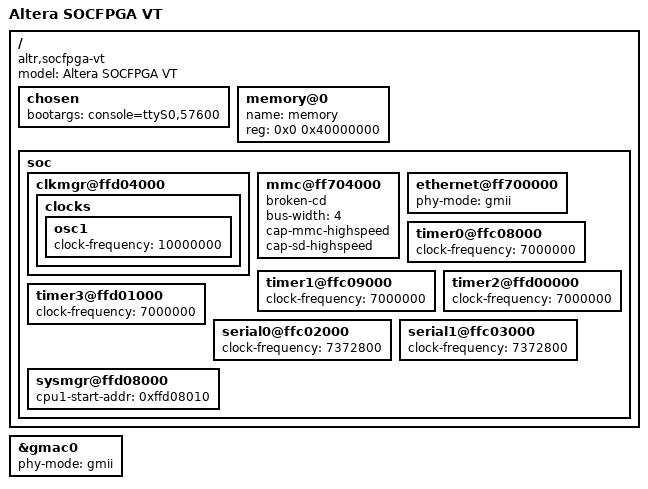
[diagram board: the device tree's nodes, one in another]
// SPDX-License-Identifier: GPL-2.0+
/*
 * Copyright (C) 2013 Altera Corporation <www.altera.com>
 */

/dts-v1/;
#include "socfpga.dtsi"

/ {
	model = "Altera SOCFPGA VT";
	compatible = "altr,socfpga-vt", "altr,socfpga";

	chosen {
		bootargs = "console=ttyS0,57600";
	};

	memory@0 {
		name = "memory";
		device_type = "memory";
		reg = <0x0 0x40000000>; /* 1 GB */
	};

	soc {
		clkmgr@ffd04000 {
			clocks {
				osc1 {
					clock-frequency = <10000000>;
				};
			};
		};

		mmc@ff704000 {
			broken-cd;
			bus-width = <4>;
			cap-mmc-highspeed;
			cap-sd-highspeed;
		};

		ethernet@ff700000 {
			phy-mode = "gmii";
			status = "okay";
		};

		timer0@ffc08000 {
			clock-frequency = <7000000>;
		};

		timer1@ffc09000 {
			clock-frequency = <7000000>;
		};

		timer2@ffd00000 {
			clock-frequency = <7000000>;
		};

		timer3@ffd01000 {
			clock-frequency = <7000000>;
		};

		serial0@ffc02000 {
			clock-frequency = <7372800>;
		};

		serial1@ffc03000 {
			clock-frequency = <7372800>;
		};

		sysmgr@ffd08000 {
			cpu1-start-addr = <0xffd08010>;
		};
	};
};

&gmac0 {
	status = "okay";
	phy-mode = "gmii";
};
